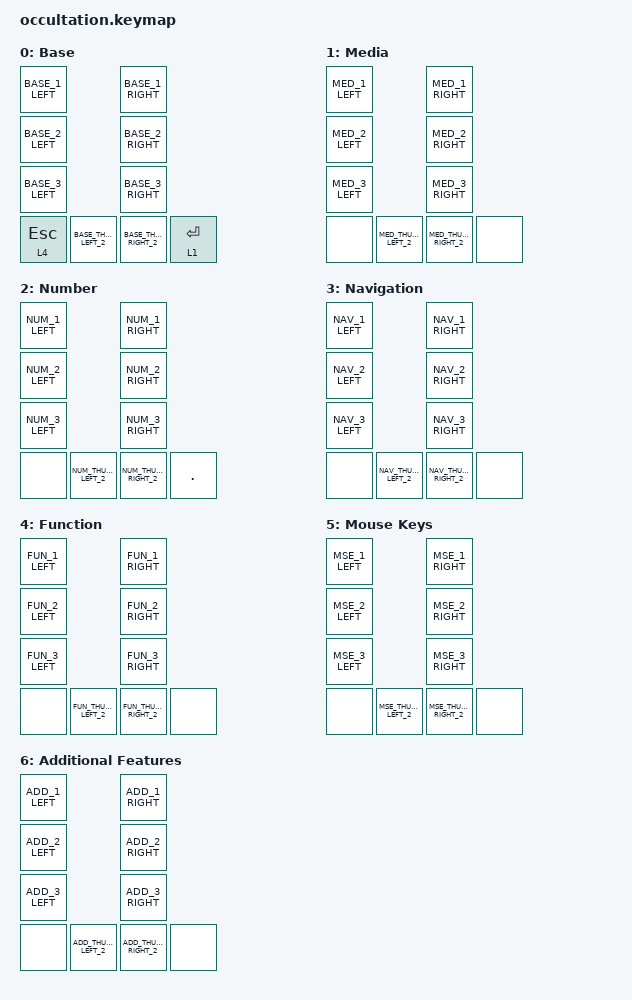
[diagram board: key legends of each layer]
/*
 * Copyright (c) 2022 The ZMK Contributors
 *
 * SPDX-License-Identifier: MIT
 */

#include <behaviors.dtsi>
#include <dt-bindings/zmk/keys.h>
#include <dt-bindings/zmk/bt.h>
#include <dt-bindings/zmk/pointing.h>
#include "aliases.h"

// hold-trigger-key-positions configs https://zmk.dev/docs/keymaps/behaviors/hold-tap?examples=home_row_mods#positional-hold-tap-and-hold-trigger-key-positions
#define KEYS_L 0 1 2 3 4  10 11 12 13 14  20 21 22 23 24
#define KEYS_R 5 6 7 8 9  15 16 17 18 19  25 26 27 28 29
#define GUI_KEYS_R 0 1 3 /* Quit, Close Window, Reload */ \
                   5 6 7 8 9 \
                   11 /* Save */ 15 16 17 18 19 \
                   25 26 27 28 29
#define THUMBS 30 31 32     33 34 35
// TODO do I want to keep the thumb combos? I might not use them on this board.
#define FUN_LAYER_COMBO_POS 30 31
#define MED_LAYER_COMBO_POS 34 35
#define STICKY_SHIFT_COMBO_POS 13 16
#include "behaviors.h" // definition of KEYS_L, KEYS_R, THUMBS must come before behaviors
#include "layers.h"

/ {
    keymap {
        compatible = "zmk,keymap";
        /*
          Layers
          0:  Base
          1:  Symbol/Media // in QMK NRM is in this position
          2:  Number
          3:  Navigation
          4:  Function
          5:  Mouse
          6:  Additional
         */
        base {
            display-name = "Base";
            bindings = <
                BASE_1_LEFT                          BASE_1_RIGHT
                BASE_2_LEFT                          BASE_2_RIGHT
                BASE_3_LEFT                          BASE_3_RIGHT
                &lt 4 ESC BASE_THUMB_LEFT_2          BASE_THUMB_RIGHT_2 &lt 1 RETURN
            >;
        };

        med { // 1
            display-name = "Media";
            bindings = <
                MED_1_LEFT                        MED_1_RIGHT
                MED_2_LEFT                        MED_2_RIGHT
                MED_3_LEFT                        MED_3_RIGHT
                &none MED_THUMB_LEFT_2            MED_THUMB_RIGHT_2 &none
            >;
        };

        num { // 2
            display-name = "Number";
            bindings = <
                NUM_1_LEFT                        NUM_1_RIGHT
                NUM_2_LEFT                        NUM_2_RIGHT
                NUM_3_LEFT                        NUM_3_RIGHT
                &none NUM_THUMB_LEFT_2            NUM_THUMB_RIGHT_2 &kp DOT
            >;
        };

        nav { // 3
            display-name = "Navigation";
            bindings = <
                NAV_1_LEFT                        NAV_1_RIGHT
                NAV_2_LEFT                        NAV_2_RIGHT
                NAV_3_LEFT                        NAV_3_RIGHT
                &none NAV_THUMB_LEFT_2            NAV_THUMB_RIGHT_2 &none
            >;
        };

        fun { // 4
            display-name = "Function";
            bindings = <
                FUN_1_LEFT                      FUN_1_RIGHT
                FUN_2_LEFT                      FUN_2_RIGHT
                FUN_3_LEFT                      FUN_3_RIGHT
                &none FUN_THUMB_LEFT_2          FUN_THUMB_RIGHT_2 &none
            >;
        };

        mse { // 5
            display-name = "Mouse Keys";
            bindings = <
                MSE_1_LEFT                        MSE_1_RIGHT
                MSE_2_LEFT                        MSE_2_RIGHT
                MSE_3_LEFT                        MSE_3_RIGHT
                &none MSE_THUMB_LEFT_2            MSE_THUMB_RIGHT_2 &none
            >;
        };

        add { // 6
            display-name = "Additional Features";
            bindings = <
                ADD_1_LEFT                           ADD_1_RIGHT
                ADD_2_LEFT                           ADD_2_RIGHT
                ADD_3_LEFT                           ADD_3_RIGHT
                &none ADD_THUMB_LEFT_2               ADD_THUMB_RIGHT_2 &none
            >;
        };
    };
};
